# PAC55XX register map
Vendor: Qorvo, Inc.; Series: PAC55XX; File version: 1.0
CPU: CM4 r0p1, little endian, MPU, FPU, vendor SysTick, 3 interrupt priority bits
Registers are 32-bit, read-write, reset 0x0 unless marked. A register's access mark holds for its fields unless they carry their own. Offsets are from the block's base; [hi:lo] are bit positions; {n}, {i} and the like mark numbered series; 'fields as' and 'values as' point back to an identical list.

## SCC — System and Clock Control
Base 0x400D0400
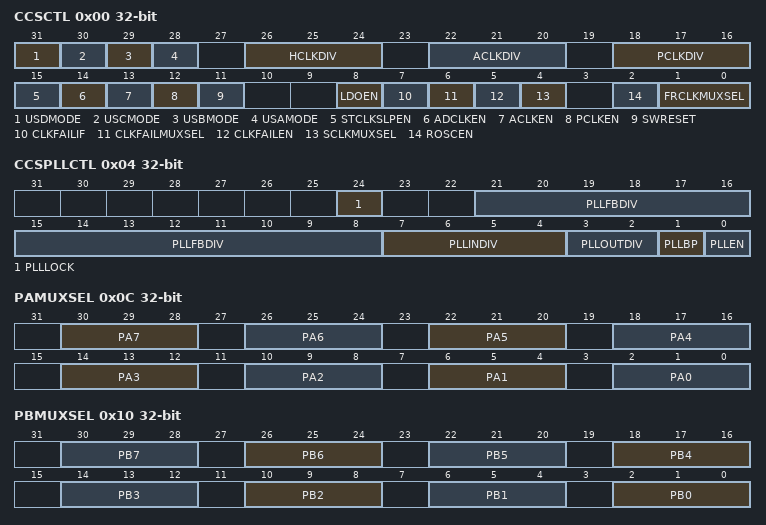
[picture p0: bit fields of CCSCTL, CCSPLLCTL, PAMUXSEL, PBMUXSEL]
0x00 CCSCTL — Configuration
  [31] USDMODE — USART D Mode
    0=SSP (SSP Mode); 1=UART (UART Mode)
  [30] USCMODE — USART C Mode
    0=SSP (SSP Mode); 1=UART (UART Mode)
  [29] USBMODE — USART B Mode
    0=SSP (SSP Mode); 1=UART (UART Mode)
  [28] USAMODE — USART A Mode
    0=SSP (SSP Mode); 1=UART (UART Mode)
  [26:24] HCLKDIV — HCLK Divider
    {v}=SCLK{v+1} (v=0..7)
  [22:20] ACLKDIV — ACLK Divider
    {v}=SCLK{v+1} (v=0..7)
  [18:16] PCLKDIV — PCLK Divider
    {v}=HCLK{v+1} (v=0..7)
  [15] STCLKSLPEN — SysTick Clock Sleep Enable
  [14] ADCLKEN — ADCCLK Enable
  [13] ACLKEN — ACLK Enable
  [12] PCLKEN — PCLK Enable
  [11] SWRESET — Software Reset
  [8] LDOEN — 1.8V LDO Enable
  [7] CLKFAILIF — Clock Fail Interrupt Flag
  [6] CLKFAILMUXSEL — Clock Fail Mux Select
    0=FRCLK (FRCLK selected as input to Clock Fail); 1=PLLCLK (PLLCLK selected as input to Clock Fail)
  [5] CLKFAILEN — Clock Fail Enable
  [4] SCLKMUXSEL — SCLK Mux Select
    0=FRCLK (FRCLK selected as input to SCLK); 1=PLLCLK (PLLCLK selected as input to SCLK)
  [2] ROSCEN — ROSC Enable
  [1:0] FRCLKMUXSEL — FRCLK MUX Select
    0=ROSC (ROSC selected as input to FRCLK); 1=CLKREF (CLKREF selected as input to FRCLK); 3=EXTCLK (External Clock selected as input to FRCLK)
0x04 CCSPLLCTL — PLL Configuration
  [24] PLLLOCK — PLL Lock Status
  [21:8] PLLFBDIV range 4..16383 — PLL Feedback Divider
  [7:4] PLLINDIV range 1..15 — PLL Input Divider
  [3:2] PLLOUTDIV — PLL Output Divider
    0=DIV1 (/1); 1=DIV2 (/2); 2=DIV4 (/4); 3=DIV8 (/8)
  [1] PLLBP — PLL Bypass
  [0] PLLEN — PLL Enable
0x08 CCSROSCTRIM — ROSC Trim Configuration
  [6:0] TRIM — ROSC Trim Value
0x0C PAMUXSEL — PA Peripheral MUX Select
  [30:28] PA7 — PA7 MUX Select
    0=GPIOA7
  [26:24] PA6 — PA6 MUX Select
    0=GPIOA6; 1=USASS (USART A SPI Slave Select); 2=USBSS (USART B SPI Slave Select)
  [22:20] PA5 — PA5 MUX Select
    0=GPIOA5; 1=USAMISO (USART A MISO/RX); 2=USBMISO (USART B MISO/RX)
  [18:16] PA4 — PA4 MUX Select
    0=GPIOA4; 1=USAMOSI (USART A MOSI/TX); 2=USBMOSI (USART B MOSI/TX)
  [14:12] PA3 — PA3 MUX Select
    0=GPIOA3; 1=USASCLK (USART A SCLK); 2=USBSCLK (USART B SCLK)
  [10:8] PA2 — PA2 MUX Select
    0=GPIOA2; 1=EMUXC (EMUX Clock)
  [6:4] PA1 — PA1 MUX Select
    0=GPIOA1; 1=EMUXD (EMUX Data)
  [2:0] PA0 — PA0 MUX Select
    0=GPIOA0
0x10 PBMUXSEL — PB Peripheral MUX Select
  [4n+2:4n] PB{n} (n=4..7) — PB{n} MUX Select
    0=GPIOB{n}; 1=TAPWM{n} (Timer A PWM{n}); 2=TBPWM{n} (Timer B PWM{n}); 3=TCPWM{n-4} (Timer C PWM{n-4}); 4=TCPWM{n} (Timer C PWM{n}); 5=TDPWM{n} (Timer D PWM{n})
  [4n+2:4n] PB{n} (n=0..3) — PB{n} MUX Select
    0=GPIOB{n}; 1=TAPWM{n} (Timer A PWM{n}); 2=TBPWM{n} (Timer B PWM{n}); 4=TCPWM{n} (Timer C PWM{n}); 5=TDPWM{n} (Timer D PWM{n})
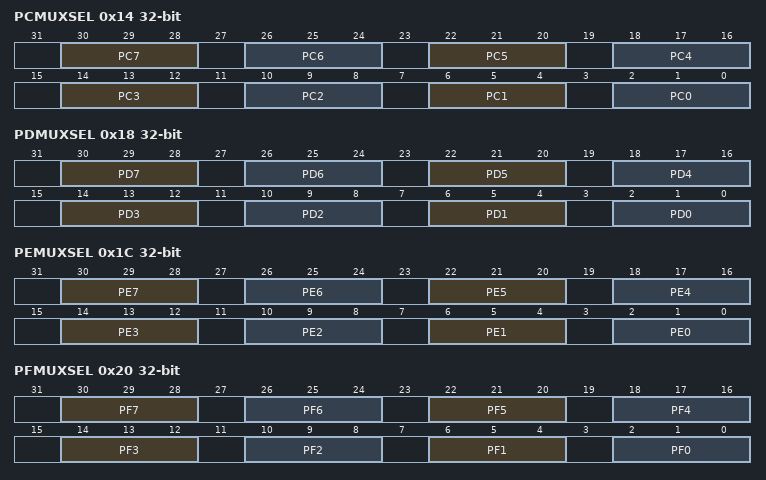
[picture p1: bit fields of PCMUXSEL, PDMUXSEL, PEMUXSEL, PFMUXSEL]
0x14 PCMUXSEL — PC Peripheral MUX Select
  [30:28] PC7 — PC7 MUX Select
    0=GPIOC7; 1=TBPWM7 (Timer B PWM7); 2=TCPWM7 (Timer C PWM7); 4=USBSS (USART B Slave Select); 5=USCMISO (USART C MISO/RX); 6=FRCLK (FRCLK Output); 7=EMUXC (EMUX Clock)
  [26:24] PC6 — PC6 MUX Select
    0=GPIOC6; 1=TBPWM6 (Timer B PWM6); 2=TCPWM6 (Timer C PWM6); 3=TCQEPPHB (Timer C QEP Phase B); 4=USBSCLK (USART B SCLK); 5=USCMOSI (USART C MOSI/TX); 7=EMUXD (EMUX Data)
  [22:20] PC5 — PC5 MUX Select
    0=GPIOC5; 1=TBPWM5 (Timer B PWM5); 2=TCPWM5 (Timer C PWM5); 3=TCQEPPHA (Timer C QEP Phase A); 4=USBMISO (USART B MISO/RX); 5=USCSS (USART C Slave Select); 6=CANTXD (CAN Tx Data); 7=I2CSDA
  [18:16] PC4 — PC4 MUX Select
    0=GPIOC4; 1=TBPWM4 (Timer B PWM4); 2=TCPWM4 (Timer C PWM4); 3=TCQEPIDX (Timer C QEP Index); 4=USBMOSI (USART B MOSI/TX); 5=USCSCLK (USART C SPI Clock); 6=CANRXD (CAN Rx Data); 7=I2CSCL
  [14:12] PC3 — PC3 MUX Select
    0=GPIOC3; 1=TBPWM3 (Timer B PWM3); 2=TCPWM3 (Timer C PWM3); 4=USBSS (USART B Slave Select); 5=USCMISO (USART C MISO/RX); 7=EMUXC (EMUX Clock)
  [10:8] PC2 — PC2 MUX Select
    0=GPIOC2; 1=TBPWM2 (Timer B PWM2); 2=TCPWM2 (Timer C PWM2); 3=TBQEPPHB (Timer B QEP Phase B); 4=USBSCLK (USART B SCLK); 5=USCMOSI (USART C MOSI/TX); 7=EMUXD (EMUX Data)
  [6:4] PC1 — PC1 MUX Select
    0=GPIOC1; 1=TBPWM1 (Timer B PWM1); 2=TCPWM1 (Timer C PWM1); 3=TBQEPPHA (Timer B QEP Phase A); 4=USBMISO (USART B MISO/RX); 5=USCSS (USART C Slave Select); 6=CANTXD (CAN Tx Data); 7=I2CSDA
  [2:0] PC0 — PC0 MUX Select
    0=GPIOC0; 1=TBPWM0 (Timer B PWM0); 2=TCPWM0 (Timer C PWM0); 3=TBQEPIDX (Timer B QEP Index); 4=USBMOSI (USART B MOSI/TX); 5=USCSCLK (USART C SPI Clock); 6=CANRXD (CAN Rx Data); 7=I2CSCL
0x18 PDMUXSEL — PD Peripheral MUX Select
  [30:28] PD7 — PD7 MUX Select
    0=GPIOD7; 1=TBPWM7 (Timer B PWM7); 2=TCPWM7 (Timer C PWM7); 5=USDMISO (USART C MISO/RX); 6=CANRXD (CAN Rx Data); 7=I2CSCL
  [26:24] PD6 — PD6 MUX Select
    0=GPIOD6; 1=TBPWM6 (Timer B PWM6); 2=TCPWM6 (Timer C PWM6); 3=TDQEPPHB (Timer D QEP Phase B); 4=TBQEPPHB (Timer B QEP Phase B); 5=USDMOSI (USART D MOSI/TX); 6=CANTXD (CAN Tx Data); 7=I2CSDA
  [22:20] PD5 — PD5 MUX Select
    0=GPIOD5; 1=TBPWM5 (Timer B PWM5); 2=TCPWM5 (Timer C PWM5); 3=TDQEPPHA (Timer D QEP Phase A); 4=TDQEPPHB (Timer D QEP Phase B); 5=USDSS (USART D Slave Select); 6=CANRXD (CAN Rx Data); 7=USDMISO (USART D MISO/RX)
  [18:16] PD4 — PD4 MUX Select
    0=GPIOD4; 1=TBPWM4 (Timer B PWM4); 2=TCPWM4 (Timer C PWM4); 3=TDQEPIDX (Timer D QEP Index); 4=TBQEPIDX (Timer B QEP Index); 5=USDSCLK (USART D SPI Clock); 6=TRACED3 (TRACE Data 3 output); 7=USDMOSI (USART D MOSI/TX)
  [14:12] PD3 — PD3 MUX Select
    0=GPIOD3; 1=TBPWM3 (Timer B PWM3); 2=TCPWM3 (Timer C PWM3); 5=USCMISO (USART C MISO/RX); 6=FRCLK (FRCLK output); 7=TRACED3 (TRACE Data 3 output)
  [10:8] PD2 — PD2 MUX Select
    0=GPIOD2; 1=TBPWM2 (Timer B PWM2); 2=TCPWM2 (Timer C PWM2); 3=TDQEPPHB (Timer D QEP Phase B); 5=USCMOSI (USART C MOSI/TX)
  [6:4] PD1 — PD1 MUX Select
    0=GPIOD1; 1=TBPWM1 (Timer B PWM1); 2=TCPWM1 (Timer C PWM1); 3=TDQEPPHA (Timer D QEP Phase A); 5=USCSS (USART C Slave Select); 6=CANRXD (CAN Rx Data); 7=EMUXC (EMUX Clock)
  [2:0] PD0 — PD0 MUX Select
    0=GPIOD0; 1=TBPWM0 (Timer B PWM0); 2=TCPWM0 (Timer C PWM0); 3=TDQEPIDX (Timer D QEP Index); 5=USCSCLK (USART C SPI Clock); 6=CANTXD (CAN Tx Data); 7=EMUXD (EMUX Data)
0x1C PEMUXSEL — PE Peripheral MUX Select
  [30:28] PE7 — PE7 MUX Select
    0=GPIOE7; 1=TCPWM7 (Timer C PWM7); 2=TDPWM7 (Timer D PWM7); 4=USBMISO (USART B MISO/RX); 5=USDSS (USART D Slave Select); 6=CANTXD (CAN TX Data)
  [26:24] PE6 — PE6 MUX Select
    0=GPIOE6; 1=TCPWM6 (Timer C PWM6); 2=TDPWM6 (Timer D PWM6); 3=TDQEPPHB (Timer D QEP Phase B); 4=USBMOSI (USART B MOSI/TX); 5=USDSCLK (USART D SCLK); 6=CANRXD (CAN RX Data)
  [22:20] PE5 — PE5 MUX Select
    0=GPIOE5; 1=TCPWM5 (Timer C PWM5); 2=TDPWM5 (Timer D PWM5); 3=TDQEPPHA (Timer D QEP Phase A); 4=USBSS (USART B Slave Select); 5=USDMISO (USART D MISO/RX); 6=I2CSDA
  [18:16] PE4 — PE4 MUX Select
    0=GPIOE4; 1=TCPWM4 (Timer C PWM4); 2=TDPWM4 (Timer D PWM4); 3=TDQEPIDX (Timer D QEP Index); 4=USBSCLK (USART B SCLK); 5=USDMOSI (USART D MOSI/TX); 6=I2CSCL
  [14:12] PE3 — PE3 MUX Select
    0=GPIOE3; 1=TCPWM7 (Timer C PWM7); 2=TDPWM3 (Timer D PWM3); 3=FRCLK (FRCLK Output); 5=USCMISO (USART C MISO/RX); 6=CANTXD (CAN Tx Data)
  [10:8] PE2 — PE2 MUX Select
    0=GPIOE2; 1=TCPWM6 (Timer C PWM6); 2=TDPWM2 (Timer D PWM2); 3=TAQEPPHB (Timer A QEP Phase B); 4=TBQEPPHB (Timer B QEP Phase B); 5=USCMOSI (USART C MOSI/TX); 6=CANRXD (CAN Rx Data); 7=EXTCLK (External clock input)
  [6:4] PE1 — PE1 MUX Select
    0=GPIOE1; 1=TCPWM5 (Timer C PWM5); 2=TDPWM1 (Timer D PWM1); 3=TAQEPPHA (Timer A QEP Phase A); 4=TBQEPPHA (Timer B QEP Phase A); 5=USCSS (USART C Slave Select); 6=I2CSDA; 7=EMUXD (EMUX Data)
  [2:0] PE0 — PE0 MUX Select
    0=GPIOE0; 1=TCPWM4 (Timer C PWM4); 2=TDPWM0 (Timer D PWM0); 3=TAQEPIDX (Timer A QEP Index); 4=TBQEPIDX (Timer B QEP Index); 5=USCSCLK (USART C SPI Clock); 6=I2CSCL; 7=EMUXC (EMUX Clock)
0x20 PFMUXSEL — PF Peripheral MUX Select
  [30:28] PF7 — PF7 MUX Select
    0=GPIOF7; 1=TCPWM7 (Timer C PWM7); 2=TDPWM7 (Timer D PWM7); 5=USDMISO (USART D MISO/RX); 6=CANTXD (CAN TX Data); 7=I2CSDA
  [26:24] PF6 — PF6 MUX Select
    0=GPIOF6; 1=TCPWM6 (Timer C PWM6); 2=TDPWM6 (Timer D PWM6); 4=TCQEPPHB (Timer C QEP Phase B); 5=USDMOSI (USART D MOSI/TX); 6=CANRXD (CAN RX Data); 7=I2CSCL
  [22:20] PF5 — PF5 MUX Select
    0=GPIOF5; 1=TCPWM5 (Timer C PWM5); 2=TDPWM5 (Timer D PWM5); 4=TCQEPPHA (Timer C QEP Phase A); 5=USDSS (USART D Slave Select); 7=EMUXD (EMUX Data)
  [18:16] PF4 — PF4 MUX Select
    0=GPIOF4; 1=TCPWM4 (Timer C PWM4); 2=TDPWM4 (Timer D PWM4); 4=TCQEPIDX (Timer C QEP Index); 5=USDSCLK (USART D SCLK); 6=TRACED3 (Trace Data 3 output); 7=EMUXC (EMUX Clock)
  [14:12] PF3 — PF3 MUX Select
    0=GPIOF3; 1=TCPWM3 (Timer C PWM3); 2=TDPWM3 (Timer D PWM3); 3=TDO (Test Data Out); 4=FRCLK (FRCLK Output); 5=USBMISO (USART B MISO/RX); 6=TRACECLK (Trace Clock); 7=TRACED2 (Trace Data 2 output)
  [10:8] PF2 — PF2 MUX Select
    0=GPIOF2; 1=TCPWM2 (Timer C PWM2); 2=TDPWM2 (Timer D PWM2); 3=TDI (Test Data In); 4=TBQEPPHB (Timer B QEP Phase B); 5=USBMOSI (USART B MOSI/TX); 6=TRACED0 (Trace Data 0 output); 7=TRACED1 (Trace Data 1 output)
  [6:4] PF1 — PF1 MUX Select
    0=GPIOF1; 1=TCPWM1 (Timer C PWM1); 2=TDPWM1 (Timer D PWM1); 3=TMS_SWDIO; 4=TBQEPPHA (Timer B QEP Phase A); 5=USBSS (USART B Slave Select); 6=TRACED1 (Trace Data 1 output); 7=TRACED0 (Trace Data 0 output)
  [2:0] PF0 — PF0 MUX Select
    0=GPIOF0; 1=TCPWM0 (Timer C PWM0); 2=TDPWM0 (Timer D PWM0); 3=TCK_SWDCLK; 4=TBQEPIDX (Timer B QEP Index); 5=USBSCLK (USART B SPI Clock); 6=TRACED2 (Trace Data 2 output); 7=TRACECLK (Trace Clock)
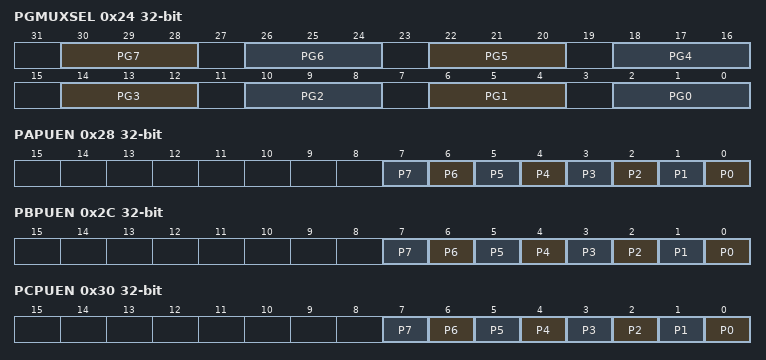
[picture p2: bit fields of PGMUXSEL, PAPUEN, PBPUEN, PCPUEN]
0x24 PGMUXSEL — PG Peripheral MUX Select
  [30:28] PG7 — PG7 MUX Select
    0=GPIOG7; 2=TDQEPIDX (Timer D QEP Index); 5=USDSCLK (USART D SPI Clock)
  [26:24] PG6 — PG6 MUX Select
    0=GPIOG6; 1=TCPWM6 (Timer C PWM6); 2=TDPWM6 (Timer D PWM6); 3=I2CSDA; 5=USDMISO (USART D MISO/RX); 6=CANTXD (CAN TX Data); 7=TDQEPPHB (Timer D QEP Phase B)
  [22:20] PG5 — PG5 MUX Select
    0=GPIOG5; 1=TCPWM5 (Timer C PWM5); 2=TDPWM5 (Timer D PWM5); 3=EMUXC (EMUX Clock); 5=USDMOSI (USART D MOSI/TX); 6=CANRXD (CAN RX Data); 7=TDQEPPHA (Timer D QEP Phase A)
  [18:16] PG4 — PG4 MUX Select
    0=GPIOG4; 1=TCPWM4 (Timer C PWM4); 2=TDPWM4 (Timer D PWM4); 3=EMUXD (EMUX Data); 4=I2CSCL; 5=USDSS (USART D Slave Select); 6=TRACED3 (Trace Data 3 output); 7=TDQEPIDX (Timer D QEP Index)
  [14:12] PG3 — PG3 MUX Select
    0=GPIOG3; 1=TCPWM3 (Timer C PWM3); 2=TDPWM3 (Timer D PWM3); 5=USDMISO (USART D MISO/RX); 6=TRACED2 (Trace Data 2 output)
  [10:8] PG2 — PG2 MUX Select
    0=GPIOG2; 1=TCPWM2 (Timer C PWM2); 2=TDPWM2 (Timer D PWM2); 3=FRCLK (FRCLK Output); 5=USDMOSI (USART D MOSI/TX); 6=TRACED1 (Trace Data 1 output); 7=TCQEPPHB (Timer C QEP Phase B)
  [6:4] PG1 — PG1 MUX Select
    0=GPIOG1; 1=TCPWM1 (Timer C PWM1); 2=TDPWM1 (Timer D PWM1); 3=EMUXD (EMUX Data); 5=USDSS (USART D Slave Select); 6=TRACED0 (Trace Data 0 output); 7=TCQEPPHA (Timer C QEP Phase A)
  [2:0] PG0 — PG0 MUX Select
    0=GPIOG0; 1=TCPWM0 (Timer C PWM0); 2=TDPWM0 (Timer D PWM0); 3=EMUXC (EMUX Clock); 5=USDSCLK (USART D SPI Clock); 6=TRACECLK (Trace Clock); 7=TCQEPIDX (Timer C QEP Index)
0x28 PAPUEN — PA Weak Pull-up Enable
  [n] P{n} (n=0..7) — Pin {n} weak pull-up enabled
0x2C PBPUEN — PB Weak Pull-up Enable
  [n] P{n} (n=0..7) — Pin {n} weak pull-up enabled
0x30 PCPUEN — PC Weak Pull-up Enable
  [n] P{n} (n=0..7) — Pin {n} weak pull-up enabled
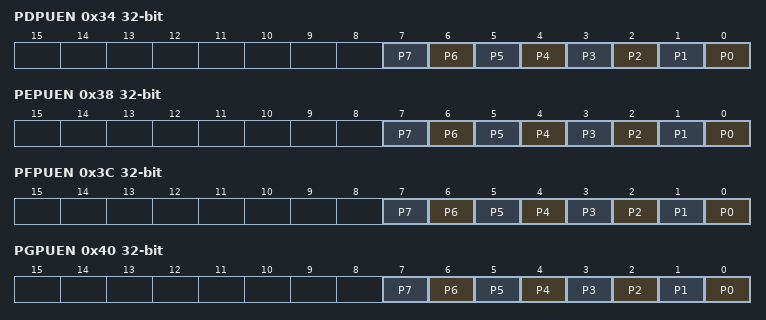
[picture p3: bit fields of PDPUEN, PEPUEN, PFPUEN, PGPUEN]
0x34 PDPUEN — PD Weak Pull-up Enable
  [n] P{n} (n=0..7) — Pin {n} weak pull-up enabled
0x38 PEPUEN — PE Weak Pull-up Enable
  [n] P{n} (n=0..7) — Pin {n} weak pull-up enabled
0x3C PFPUEN — PF Weak Pull-up Enable
  [n] P{n} (n=0..7) — Pin {n} weak pull-up enabled
0x40 PGPUEN — PG Weak Pull-up Enable
  [n] P{n} (n=0..7) — Pin {n} weak pull-up enabled
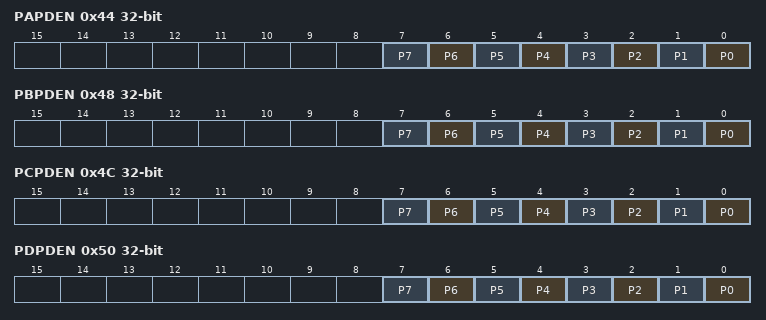
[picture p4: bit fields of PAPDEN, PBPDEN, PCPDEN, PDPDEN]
0x44 PAPDEN — PA Weak Pull-down Enable
  [n] P{n} (n=0..7) — Pin {n} weak pull-down enabled
0x48 PBPDEN — PB Weak Pull-down Enable
  [n] P{n} (n=0..7) — Pin {n} weak pull-down enabled
0x4C PCPDEN — PC Weak Pull-down Enable
  [n] P{n} (n=0..7) — Pin {n} weak pull-down enabled
0x50 PDPDEN — PD Weak Pull-down Enable
  [n] P{n} (n=0..7) — Pin {n} weak pull-down enabled
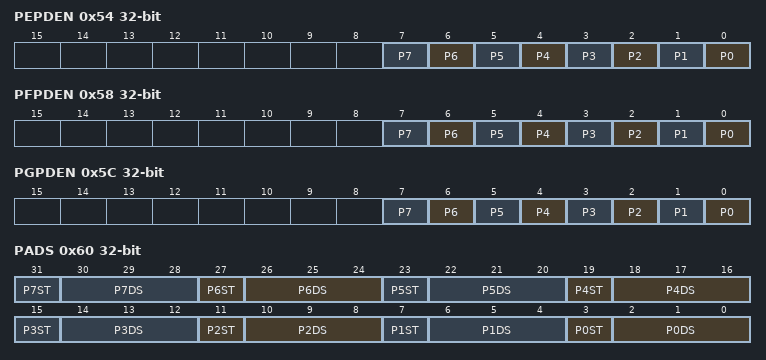
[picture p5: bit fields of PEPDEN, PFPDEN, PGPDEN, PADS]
0x54 PEPDEN — PE Weak Pull-down Enable
  [n] P{n} (n=0..7) — Pin {n} weak pull-down enabled
0x58 PFPDEN — PF Weak Pull-down Enable
  [n] P{n} (n=0..7) — Pin {n} weak pull-down enabled
0x5C PGPDEN — PG Weak Pull-down Enable
  [n] P{n} (n=0..7) — Pin {n} weak pull-down enabled
0x60 PADS — PA Drive Strength/Schmitt Trigger
  [4n+3] P{n}ST (n=0..7) — Pin {n} Schmitt Trigger Enable
  [4n+2:4n] P{n}DS (n=0..7) — Pin {n} Drive Strength
    0=DS_6MA (6 mA); 1=DS_8MA (8 mA); 2=DS_11MA (11 mA); 3=DS_14MA (14 mA); 4=DS_17MA (17 mA); 5=DS_20MA (20 mA); 6=DS_22MA (22 mA); 7=DS_25MA (25 mA)
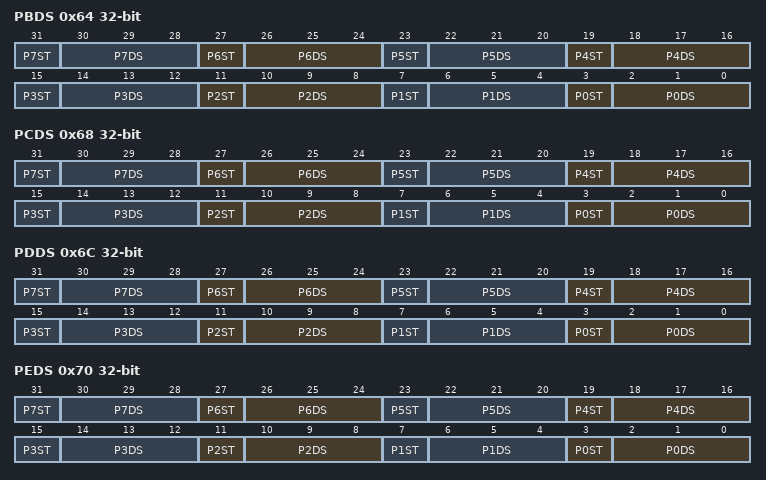
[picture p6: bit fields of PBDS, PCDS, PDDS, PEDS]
0x64 PBDS — PB Drive Strength/Schmitt Trigger
  fields as PADS
0x68 PCDS — PC Drive Strength/Schmitt Trigger
  fields as PADS
0x6C PDDS — PD Drive Strength/Schmitt Trigger
  fields as PADS
0x70 PEDS — PE Drive Strength/Schmitt Trigger
  fields as PADS
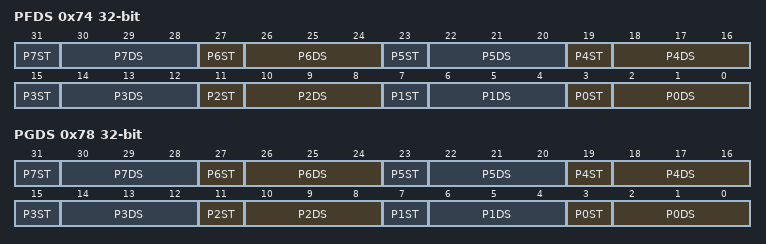
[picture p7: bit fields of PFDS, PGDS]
0x74 PFDS — PF Drive Strength/Schmitt Trigger
  fields as PADS
0x78 PGDS — PG Drive Strength/Schmitt Trigger
  fields as PADS
